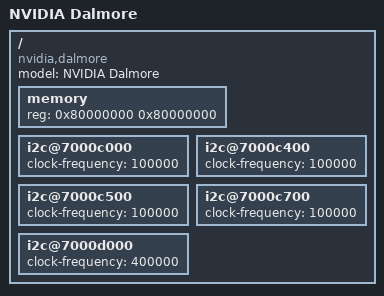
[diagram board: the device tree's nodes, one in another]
/dts-v1/;

#include "tegra114.dtsi"

/ {
	model = "NVIDIA Dalmore";
	compatible = "nvidia,dalmore", "nvidia,tegra114";

	memory {
		device_type = "memory";
		reg = <0x80000000 0x80000000>;
	};

	i2c@7000c000 {
		status = "okay";
		clock-frequency = <100000>;
	};

	i2c@7000c400 {
		status = "okay";
		clock-frequency = <100000>;
	};

	i2c@7000c500 {
		status = "okay";
		clock-frequency = <100000>;
	};

	i2c@7000c700 {
		status = "okay";
		clock-frequency = <100000>;
	};

	i2c@7000d000 {
		status = "okay";
		clock-frequency = <400000>;
	};
};
